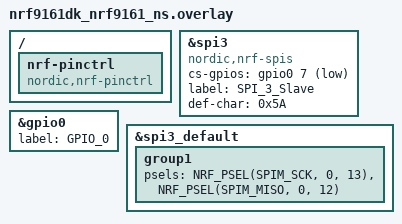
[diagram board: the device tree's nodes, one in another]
&spi3 {
    compatible = "nordic,nrf-spis";
    status = "okay";
    cs-gpios = <&gpio0 7 GPIO_ACTIVE_LOW>; // Pin para CS
    label = "SPI_3_Slave";
    def-char = <0x5A>; // Caracter de inicio de trama
};

&gpio0 {
    status = "okay";
    label = "GPIO_0";
};


&spi3_default {
    group1 {
        psels = <NRF_PSEL(SPIM_SCK, 0, 13)>, <NRF_PSEL(SPIM_MISO, 0, 12)>;
    };
};

/ {
    nrf-pinctrl {
        compatible = "nordic,nrf-pinctrl";
    };
};
